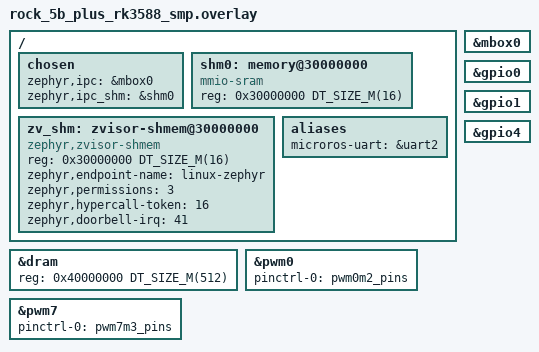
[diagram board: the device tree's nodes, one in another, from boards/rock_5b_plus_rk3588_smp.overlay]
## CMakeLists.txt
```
# SPDX-License-Identifier: Apache-2.0

cmake_minimum_required(VERSION 3.13.1)

# Backend selection: the real DDS (micro-ROS) backend is the default.
# Build the stub instead with -DHEARTBEAT_STUB=y.
if(HEARTBEAT_STUB)
  set(CONFIG_DEMO_HEARTBEAT_STUB y CACHE STRING "" FORCE)
endif()

# The micro-ROS library module is always registered so its Kconfig symbols
# exist during the configuration phase; the library is only linked when
# CONFIG_MICROROS=y (selected by CONFIG_DEMO_HEARTBEAT_MICROROS).
list(APPEND ZEPHYR_EXTRA_MODULES ${CMAKE_CURRENT_SOURCE_DIR}/modules/libmicroros)

find_package(Zephyr REQUIRED HINTS $ENV{ZEPHYR_BASE})
project(pwm_dds_demo)

target_sources(app PRIVATE
	src/main.c
	src/signal_chain.c
)

if(CONFIG_DEMO_SHELL)
  target_sources(app PRIVATE src/dds_shell.c src/hb_shell.c)
endif()

if(CONFIG_DEMO_HEARTBEAT_STUB)
  target_sources(app PRIVATE src/dds_stub.c)
elseif(CONFIG_DEMO_HEARTBEAT_MICROROS)
  target_sources(app PRIVATE src/dds_microros.c)
endif()
```

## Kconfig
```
# PWM/DDS demo application Kconfig.
#
# When an application provides its own Kconfig it becomes the Kconfig root,
# so the Zephyr core tree must be sourced explicitly.

mainmenu "PWM/DDS demo"

source "Kconfig.zephyr"

menu "PWM/DDS demo"

config DEMO_HEARTBEAT_STUB
	bool "Stub heartbeat backend (simulated Linux round trip)"
	default n
	help
	  Use the stub backend instead of the real micro-ROS DDS link.
	  Enable at build time with -DHEARTBEAT_STUB=y.

config DEMO_HEARTBEAT_MICROROS
	bool
	default y if !DEMO_HEARTBEAT_STUB
	select MICROROS
	select CPP
	select POSIX_API

config DEMO_SHELL
	bool "Demo shell (dds diagnostics + hb tuning)"
	default y
	help
	  Enable the demo shell command sets:
	  - "dds" diagnostics (status/stats/shm) for the heartbeat link;
	  - "hb" business tuning (period/freq) for the signal chain.
	  Requires CONFIG_SHELL=y (see prj.conf).

config DEMO_CONTROL_PERIOD_MS
	int "Signal-chain control period default (ms)"
	default 50
	range 1 1000
	help
	  Default control period of the signal chain (GPIO/PWM/heartbeat
	  cadence).  TEMPORARY debugging value: 50 ms while the DDS link
	  is being brought up; restore to 1 ms afterwards.  Can be
	  overridden at runtime with "hb period <ms>" / "hb freq <hz>".

config DEMO_RK_TIMER
	bool "Use the RK3588 bus timer for the control tick (hard real-time)"
	default n
	help
	  Drive the signal chain tick from the RK3588 bus timer (timer0)
	  counter driver instead of the systick k_timer.  The hardware
	  auto-reload fires the 1 ms callback with no software re-arm
	  jitter, and supports sub-millisecond periods (hb period accepts
	  them; the systick path is limited to >= 1 ms).

	  Requires the rockchip counter driver and the timer0 devicetree
	  node in the Zephyr tree (commits on wip/hongquan.li/
	  ProcessONE-RTOS-Demo, archived at gerrit wip/libryan/pwm-rk3588).
	  Default n so builds against Zephyr trees without the driver keep
	  working.

endmenu
```

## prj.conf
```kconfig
# PWM/DDS demo configuration.
#
# The heartbeat backend defaults to the real DDS (micro-ROS) via the
# Kconfig choice; build the stub variant with -DCONFIG_DEMO_HEARTBEAT_STUB=y
# (or the -DDDS_STUB=y alias).

CONFIG_GPIO=y
CONFIG_PWM=y
CONFIG_PWM_ROCKCHIP=y

# 1 ms systick for the signal chain.
CONFIG_SYS_CLOCK_TICKS_PER_SEC=1000

# Console/log output.
CONFIG_SERIAL=y
CONFIG_CONSOLE=y
CONFIG_UART_CONSOLE=y
CONFIG_STDOUT_CONSOLE=y
CONFIG_LOG=y

# Newlib (required by micro-ROS; the stub build uses it too so the two
# backends share a single libc).
CONFIG_NEWLIB_LIBC=y

# Pin the signal-chain thread to CPU0 (same core as the tick interrupt):
# no cross-core wakeup latency/jitter in the GPIO1->GPIO2 leg.
CONFIG_SCHED_CPU_MASK=y
CONFIG_SCHED_CPU_MASK_PIN_ONLY=y

# Counter subsystem (used when DEMO_RK_TIMER=y drives the tick from the
# RK3588 bus timer; harmless when the systick path is active).
CONFIG_COUNTER=y

# Demo shell: "dds" diagnostics (status/stats/shm) + "hb" tuning (period/freq).
# Interrupt-driven serial backend is disabled: the RK3588 uart2 IRQ mode
# hangs at boot (see TODO #9); the polling backend works.
CONFIG_SHELL=y
CONFIG_SHELL_BACKEND_SERIAL_INTERRUPT_DRIVEN=n
# Keep the shell below the control thread (prio 0) so typing commands
# does not perturb the 1 ms signal chain.
CONFIG_SHELL_THREAD_PRIORITY_OVERRIDE=y
CONFIG_SHELL_THREAD_PRIORITY=5
```

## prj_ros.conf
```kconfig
# Phase 2 (real DDS over micro-ROS) extra configuration.
# Build with: -DEXTRA_CONF_FILE=prj_ros.conf
#
# Transport: ZVisor shared-memory VM channel between the zephyr guest and
# Linux (see the zv_shm node in the board overlay; HVC doorbell on TX,
# virtual IRQ 41 on RX).

CONFIG_DEMO_HEARTBEAT_MICROROS=y

# micro-ROS runtime requirements.
CONFIG_CPP=y
CONFIG_NEWLIB_LIBC=y
CONFIG_NEWLIB_LIBC_NANO=n
CONFIG_POSIX_API=y

# ZVisor shared-memory transport.
CONFIG_MICROROS_TRANSPORT_ZVISOR_SHMEM=y
```

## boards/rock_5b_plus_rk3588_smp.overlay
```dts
/*
 * Board wiring for the micro-ROS transports on ROCK 5B+.
 *
 * The Zephyr console/shell stays on uart2 (see the chosen node in
 * rock_5b_plus.dts). Two micro-ROS transports are wired up here; the
 * active one is selected by Kconfig (CONFIG_MICROROS_TRANSPORT_*):
 *
 * 1. OpenAMP/RPMsg (QEMU demo): vrings and buffers live in the 16MB
 *    shared memory window at 0x30000000, doorbells go through the
 *    mailbox at 0xFE380000 (GIC SPI 219 towards this side).
 *
 * 2. ZVisor shared memory (hypervisor demo): one 16MB GPA window
 *    provided by ZVisor, split into two fixed halves. Zephyr writes
 *    requests into the first half and rings the doorbell with
 *    HVC 0x86000000 + token 16 (raises Linux IRQ 42); Linux writes
 *    responses into the second half and rings token 32, which raises
 *    Zephyr IRQ 41.
 *
 * Physical memory map of this setup:
 *   [0x30000000, 0x30800000)  RPMsg shm / ZVisor request window (8MB)
 *   [0x30800000, 0x31000000)  ZVisor response window (8MB)
 *   [0x40000000, 0x60000000)  Zephyr DRAM (512MB, this image)
 */

/ {
	chosen {
		zephyr,ipc = &mbox0;
		zephyr,ipc_shm = &shm0;
	};

	shm0: memory@30000000 {
		compatible = "mmio-sram";
		reg = <0x30000000 DT_SIZE_M(16)>;
	};

	zv_shm: zvisor-shmem@30000000 {
		compatible = "zephyr,zvisor-shmem";
		reg = <0x30000000 DT_SIZE_M(16)>;
		zephyr,endpoint-name = "linux-zephyr";
		zephyr,permissions = <3>;
		zephyr,hypercall-token = <16>;
		zephyr,doorbell-irq = <41>;
	};
};

&mbox0 {
	status = "okay";
};

&dram {
	reg = <0x40000000 DT_SIZE_M(512)>;
};

/* --- Phase 1 signal-chain wiring (PWM/DDS demo) ------------------------ */
&pwm0 {
	status = "okay";
	pinctrl-0 = <&pwm0m2_pins>;
	pinctrl-names = "default";
};

&pwm7 {
	status = "okay";
	pinctrl-0 = <&pwm7m3_pins>;
	pinctrl-names = "default";
};

&gpio0 {
	status = "okay";
};

&gpio1 {
	status = "okay";
};

&gpio4 {
	status = "okay";
};

/* micro-ROS serial transport UART (aliased per the transport's Kconfig
 * contract; uart2 is the board debug UART on the 40-pin header). */
/ {
	aliases {
		microros-uart = &uart2;
	};
};
```

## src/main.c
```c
/*
 * SPDX-License-Identifier: Apache-2.0
 * Copyright (c) 2026 Process Mission
 *
 * ProcessONE GPIO/PWM and DDS integration demo entry point.
 */

#include <zephyr/kernel.h>
#include <zephyr/logging/log.h>

#include "signal_chain.h"

LOG_MODULE_REGISTER(main, LOG_LEVEL_INF);

int main(void)
{
	if (IS_ENABLED(CONFIG_DEMO_HEARTBEAT_MICROROS)) {
		LOG_INF("ProcessONE PWM/DDS demo starting (real SHM DDS)");
	} else {
		LOG_INF("ProcessONE PWM/DDS demo starting (stub heartbeat)");
	}

	if (signal_chain_init() != 0) {
		LOG_ERR("signal chain init failed");
		return -1;
	}

	return 0;
}
```

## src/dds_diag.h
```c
/*
 * SPDX-License-Identifier: Apache-2.0
 * Copyright (c) 2026 Process Mission
 *
 * Read-only diagnostic snapshots exposed by the DDS and signal-chain
 * modules for the "dds" shell command set.
 */

#ifndef DDS_DIAG_H
#define DDS_DIAG_H

#include <zephyr/sys/util.h>

#include <stdbool.h>
#include <stdint.h>

/* One-line thread state strings. */
#define DDS_DIAG_THREAD_STATE_LEN 24

struct dds_diag {
	/* Session / entity state. */
	bool initialized;
	bool session_ready;
	uint8_t entity_ready_mask;	/* bit0 support .. bit5 executor subscription */
	uint32_t session_rebuilds;
	uint32_t publish_failures;
	uint32_t ping_failures_total;

	/* TX pending slot (latest value only). */
	uint32_t pending_tx_seq;
	bool tx_pending;

	/* RX side. */
	int32_t received_linux_seq;
	uint32_t recv_sem_count;	/* queued, not yet handled replies */

	/* Threads. */
	char supervisor_state[DDS_DIAG_THREAD_STATE_LEN];
	char reply_state[DDS_DIAG_THREAD_STATE_LEN];
	size_t supervisor_stack_free;
	size_t reply_stack_free;
};

struct signal_chain_diag {
	uint32_t timer_ticks;
	uint32_t control_count;
	uint32_t missed_ticks;
	uint32_t tx_seq;		/* zephyr heartbeat seq sent */
	uint32_t rx_count;		/* linux heartbeats received */
	uint32_t last_linux_seq;
	uint32_t gpio_errors;
	uint32_t pwm_errors;
	uint32_t tx_offline;		/* hb_send -ENOTCONN count */
};

#if IS_ENABLED(CONFIG_DEMO_HEARTBEAT_MICROROS)
void dds_get_diag(struct dds_diag *out);
#endif

void signal_chain_get_diag(struct signal_chain_diag *out);

#endif /* DDS_DIAG_H */
```

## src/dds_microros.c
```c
/*
 * SPDX-License-Identifier: Apache-2.0
 * Copyright (c) 2026 Process Mission
 *
 * Real bidirectional heartbeat over micro-ROS and the ZVisor shared-memory
 * transport. The two directions use separate topics:
 *
 *   Zephyr -> Linux: /zephyr_int32_publisher
 *   Linux  -> Zephyr: /host_int32_publisher
 *
 * The micro-ROS entities are owned by one supervisor thread. hb_send() only
 * replaces the pending sequence number, so the signal-chain thread never
 * blocks in DDS and stale heartbeats do not accumulate while the Agent is
 * unavailable. When the Agent disconnects, the supervisor tears down and
 * recreates the session without restarting the GPIO/PWM threads.
 */

#include <errno.h>
#include <stdbool.h>
#include <string.h>

#include <rcl/rcl.h>
#include <rcl/error_handling.h>
#include <rclc/executor.h>
#include <rclc/rclc.h>
#include <rmw_microros/rmw_microros.h>
#include <std_msgs/msg/int32.h>

#include <microros_transports.h>

#include <zephyr/kernel.h>
#include <zephyr/logging/log.h>
#include <zephyr/sys/atomic.h>

#include "heartbeat_dds.h"
#include "dds_diag.h"

LOG_MODULE_REGISTER(dds_microros, LOG_LEVEL_INF);

#define ZEPHYR_HEARTBEAT_TOPIC "zephyr_int32_publisher"
#define LINUX_HEARTBEAT_TOPIC   "host_int32_publisher"
#define NODE_NAME               "processone_zephyr_heartbeat"

#define AGENT_WAIT_INTERVAL_MS   250
#define AGENT_PING_INTERVAL_MS   500
#define AGENT_PING_TIMEOUT_MS    100
#define AGENT_PING_FAILURE_LIMIT 2
#define EXECUTOR_SPIN_TIMEOUT_NS RCL_MS_TO_NS(1)
#define MICROROS_STACK_SIZE      24576
#define REPLY_STACK_SIZE         1024
#define REPLY_THREAD_PRIORITY    4

struct microros_entities {
	rclc_support_t support;
	rcl_node_t node;
	rcl_publisher_t publisher;
	rcl_subscription_t subscriber;
	rclc_executor_t executor;
	bool support_ready;
	bool node_ready;
	bool publisher_ready;
	bool subscriber_ready;
	bool executor_ready;
};

static struct microros_entities entities;
static std_msgs__msg__Int32 tx_msg;
static std_msgs__msg__Int32 rx_msg;
static hb_recv_cb_t recv_cb;

K_SEM_DEFINE(recv_sem, 0, K_SEM_MAX_LIMIT);
static atomic_t received_linux_seq;
static atomic_t session_ready;
static atomic_t initialized;

/* Diagnostic counters (read via dds_get_diag()). */
static atomic_t session_rebuilds;
static atomic_t publish_failures;
static atomic_t ping_failures_total;

static struct k_spinlock tx_lock;
static uint32_t pending_tx_seq;
static bool tx_pending;

K_THREAD_STACK_DEFINE(microros_stack, MICROROS_STACK_SIZE);
static struct k_thread microros_thread_data;

K_THREAD_STACK_DEFINE(reply_stack, REPLY_STACK_SIZE);
static struct k_thread reply_thread_data;

static void log_entity_ready(uint8_t ordinal, const char *step)
{
	LOG_DBG("DDS entity %u/6 ready: %s", ordinal, step);
}

static void log_rcl_failure(uint8_t ordinal, const char *step,
			    rcl_ret_t result)
{
	rcl_error_string_t error = rcl_get_error_string();
	const char *detail = error.str[0] != '\0' ? error.str : "not set";

	LOG_WRN("DDS entity %u/6 failed: %s result=%d detail='%s'",
		ordinal, step, (int)result, detail);
}

static void entities_reset(struct microros_entities *ctx)
{
	memset(ctx, 0, sizeof(*ctx));
	ctx->node = rcl_get_zero_initialized_node();
	ctx->publisher = rcl_get_zero_initialized_publisher();
	ctx->subscriber = rcl_get_zero_initialized_subscription();
	ctx->executor = rclc_executor_get_zero_initialized_executor();
}

static void cleanup_result(const char *operation, rcl_ret_t result)
{
	if (result == RCL_RET_OK) {
		return;
	}

	LOG_WRN("cleanup %s returned %d", operation, (int)result);
	rcl_reset_error();
}

static void destroy_entities(struct microros_entities *ctx)
{
	atomic_clear(&session_ready);

	if (ctx->support_ready) {
		rmw_context_t *rmw_context =
			rcl_context_get_rmw_context(&ctx->support.context);

		if (rmw_context != NULL) {
			(void)rmw_uros_set_context_entity_destroy_session_timeout(
				rmw_context, 0);
		}
	}

	if (ctx->executor_ready) {
		cleanup_result("executor", rclc_executor_fini(&ctx->executor));
	}
	if (ctx->subscriber_ready) {
		cleanup_result("subscriber",
			       rcl_subscription_fini(&ctx->subscriber, &ctx->node));
	}
	if (ctx->publisher_ready) {
		cleanup_result("publisher",
			       rcl_publisher_fini(&ctx->publisher, &ctx->node));
	}
	if (ctx->node_ready) {
		cleanup_result("node", rcl_node_fini(&ctx->node));
	}
	if (ctx->support_ready) {
		cleanup_result("support", rclc_support_fini(&ctx->support));
	}

	entities_reset(ctx);
}

static void reply_thread(void *arg1, void *arg2, void *arg3)
{
	ARG_UNUSED(arg1);
	ARG_UNUSED(arg2);
	ARG_UNUSED(arg3);

	while (true) {
		k_sem_take(&recv_sem, K_FOREVER);
		if (recv_cb != NULL) {
			recv_cb((uint32_t)atomic_get(&received_linux_seq));
		}
	}
}

static void subscription_callback(const void *message)
{
	const std_msgs__msg__Int32 *received = message;

	atomic_set(&received_linux_seq, (atomic_val_t)received->data);
	/* Preserve one GPIO/PWM action per real DDS reply.  Unlike a single
	 * k_work item, the counting semaphore does not coalesce replies that
	 * arrive while the handler is already running. */
	k_sem_give(&recv_sem);
}

static bool create_entities(struct microros_entities *ctx,
			    rcl_allocator_t *allocator)
{
	rcl_ret_t result;
	const char *failed_step = "support";
	uint8_t failed_ordinal = 1U;

	entities_reset(ctx);

	result = rclc_support_init(&ctx->support, 0, NULL, allocator);
	if (result != RCL_RET_OK) {
		goto fail;
	}
	ctx->support_ready = true;
	log_entity_ready(1U, "support");

	failed_step = "node";
	failed_ordinal = 2U;
	result = rclc_node_init_default(&ctx->node, NODE_NAME, "", &ctx->support);
	if (result != RCL_RET_OK) {
		goto fail;
	}
	ctx->node_ready = true;
	log_entity_ready(2U, "node");

	failed_step = "publisher";
	failed_ordinal = 3U;
	result = rclc_publisher_init_best_effort(
		&ctx->publisher, &ctx->node,
		ROSIDL_GET_MSG_TYPE_SUPPORT(std_msgs, msg, Int32),
		ZEPHYR_HEARTBEAT_TOPIC);
	if (result != RCL_RET_OK) {
		goto fail;
	}
	ctx->publisher_ready = true;
	log_entity_ready(3U, "publisher /" ZEPHYR_HEARTBEAT_TOPIC);

	failed_step = "subscriber";
	failed_ordinal = 4U;
	result = rclc_subscription_init_best_effort(
		&ctx->subscriber, &ctx->node,
		ROSIDL_GET_MSG_TYPE_SUPPORT(std_msgs, msg, Int32),
		LINUX_HEARTBEAT_TOPIC);
	if (result != RCL_RET_OK) {
		goto fail;
	}
	ctx->subscriber_ready = true;
	log_entity_ready(4U, "subscriber /" LINUX_HEARTBEAT_TOPIC);

	failed_step = "executor";
	failed_ordinal = 5U;
	result = rclc_executor_init(&ctx->executor, &ctx->support.context, 1,
				    allocator);
	if (result != RCL_RET_OK) {
		goto fail;
	}
	ctx->executor_ready = true;
	log_entity_ready(5U, "executor");

	failed_step = "executor subscription";
	failed_ordinal = 6U;
	result = rclc_executor_add_subscription(
		&ctx->executor, &ctx->subscriber, &rx_msg,
		subscription_callback, ON_NEW_DATA);
	if (result != RCL_RET_OK) {
		goto fail;
	}
	log_entity_ready(6U, "executor subscription");

	atomic_set(&session_ready, 1);
	LOG_INF("Agent connected: tx=/%s rx=/%s",
		ZEPHYR_HEARTBEAT_TOPIC, LINUX_HEARTBEAT_TOPIC);
	return true;

fail:
	log_rcl_failure(failed_ordinal, failed_step, result);
	rcl_reset_error();
	zephyr_transport_set_session_active(true);
	destroy_entities(ctx);
	zephyr_transport_set_session_active(false);
	return false;
}

static bool take_pending_sequence(uint32_t *sequence)
{
	k_spinlock_key_t key = k_spin_lock(&tx_lock);
	bool pending = tx_pending;

	if (pending) {
		*sequence = pending_tx_seq;
		tx_pending = false;
	}
	k_spin_unlock(&tx_lock, key);
	return pending;
}

static bool publish_pending_sequence(void)
{
	uint32_t sequence;
	rcl_ret_t result;

	if (!take_pending_sequence(&sequence)) {
		return true;
	}

	tx_msg.data = (int32_t)sequence;
	result = rcl_publish(&entities.publisher, &tx_msg, NULL);
	if (result == RCL_RET_OK) {
		return true;
	}

	atomic_inc(&publish_failures);
	LOG_WRN("publish failed (%d), reconnecting", (int)result);
	rcl_reset_error();
	return false;
}

static void microros_thread(void *arg1, void *arg2, void *arg3)
{
	rcl_allocator_t allocator = rcl_get_default_allocator();

	ARG_UNUSED(arg1);
	ARG_UNUSED(arg2);
	ARG_UNUSED(arg3);

	LOG_INF("waiting for Micro-XRCE-DDS Agent");
	while (true) {
		int64_t next_ping_ms;
		uint8_t ping_failures = 0;
		bool session_error = false;

		while (!create_entities(&entities, &allocator)) {
			k_sleep(K_MSEC(AGENT_WAIT_INTERVAL_MS));
		}

		zephyr_transport_set_session_active(true);
		next_ping_ms = k_uptime_get() + AGENT_PING_INTERVAL_MS;

		while (!session_error) {
			rcl_ret_t result = rclc_executor_spin_some(
				&entities.executor, EXECUTOR_SPIN_TIMEOUT_NS);
			int64_t now_ms = k_uptime_get();

			if (result != RCL_RET_OK && result != RCL_RET_TIMEOUT) {
				LOG_WRN("executor failed (%d), reconnecting",
					(int)result);
				rcl_reset_error();
				session_error = true;
			}

			if (!session_error && !publish_pending_sequence()) {
				session_error = true;
			}

			if (!session_error && now_ms >= next_ping_ms) {
				if (rmw_uros_ping_agent(AGENT_PING_TIMEOUT_MS, 1) ==
				    RMW_RET_OK) {
					ping_failures = 0;
				} else {
					atomic_inc(&ping_failures_total);
					if (++ping_failures >=
					    AGENT_PING_FAILURE_LIMIT) {
						session_error = true;
					}
				}
				next_ping_ms = now_ms + AGENT_PING_INTERVAL_MS;
			}


			/* A 1 ms executor wait bounds reply handling latency while still
			 * blocking on the SHM RX doorbell instead of busy polling. */
			if (!session_error) {
				k_yield();
			}
		}

		LOG_WRN("Agent disconnected, rebuilding entities");
		atomic_inc(&session_rebuilds);
		destroy_entities(&entities);
		zephyr_transport_set_session_active(false);
		k_sleep(K_MSEC(AGENT_WAIT_INTERVAL_MS));
	}
}

int hb_init(hb_recv_cb_t cb)
{
	if (!atomic_cas(&initialized, 0, 1)) {
		return -EALREADY;
	}

	recv_cb = cb;
	entities_reset(&entities);
	atomic_clear(&received_linux_seq);
	atomic_clear(&session_ready);

	k_thread_create(&reply_thread_data, reply_stack,
			K_THREAD_STACK_SIZEOF(reply_stack), reply_thread,
			NULL, NULL, NULL, K_PRIO_PREEMPT(REPLY_THREAD_PRIORITY),
			0, K_NO_WAIT);

	rmw_uros_set_custom_transport(
		MICRO_ROS_FRAMING_REQUIRED,
		(void *)&default_params,
		zephyr_transport_open,
		zephyr_transport_close,
		zephyr_transport_write,
		zephyr_transport_read);

	k_thread_create(&microros_thread_data, microros_stack,
			K_THREAD_STACK_SIZEOF(microros_stack), microros_thread,
			NULL, NULL, NULL, K_PRIO_PREEMPT(5), 0, K_NO_WAIT);

	return 0;
}

int hb_send(uint32_t seq)
{
	k_spinlock_key_t key = k_spin_lock(&tx_lock);

	pending_tx_seq = seq;
	tx_pending = true;
	k_spin_unlock(&tx_lock, key);

	return atomic_get(&session_ready) != 0 ? 0 : -ENOTCONN;
}

void dds_get_diag(struct dds_diag *out)
{
	k_spinlock_key_t key;

	out->initialized = atomic_get(&initialized) != 0;
	out->session_ready = atomic_get(&session_ready) != 0;
	out->entity_ready_mask = 0;
	if (entities.support_ready) {
		out->entity_ready_mask |= BIT(0);
	}
	if (entities.node_ready) {
		out->entity_ready_mask |= BIT(1);
	}
	if (entities.publisher_ready) {
		out->entity_ready_mask |= BIT(2);
	}
	if (entities.subscriber_ready) {
		out->entity_ready_mask |= BIT(3);
	}
	if (entities.executor_ready) {
		out->entity_ready_mask |= BIT(4);
	}
	out->session_rebuilds = atomic_get(&session_rebuilds);
	out->publish_failures = atomic_get(&publish_failures);
	out->ping_failures_total = atomic_get(&ping_failures_total);

	key = k_spin_lock(&tx_lock);
	out->pending_tx_seq = pending_tx_seq;
	out->tx_pending = tx_pending;
	k_spin_unlock(&tx_lock, key);

	out->received_linux_seq = (int32_t)atomic_get(&received_linux_seq);
	out->recv_sem_count = k_sem_count_get(&recv_sem);

	k_thread_state_str(&microros_thread_data, out->supervisor_state,
			   sizeof(out->supervisor_state));
	k_thread_state_str(&reply_thread_data, out->reply_state,
			   sizeof(out->reply_state));
	k_thread_stack_space_get(&microros_thread_data,
				 &out->supervisor_stack_free);
	k_thread_stack_space_get(&reply_thread_data, &out->reply_stack_free);
}
```

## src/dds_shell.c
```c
/*
 * SPDX-License-Identifier: Apache-2.0
 * Copyright (c) 2026 Process Mission
 *
 * "dds" diagnostic shell for the PWM/DDS demo.
 *
 *   dds status               session/entity/slot/thread snapshot
 *   dds stats [reset]        signal-chain, DDS and transport counters
 *   dds shm [dump [n]]       shmem slot states; hexdump of the rsp window
 *
 * The slot states are read straight from the zvisor-shmem windows (the
 * windows are mapped cache-none device memory and the GPA is fixed by
 * the devicetree), so the transport module does not need to expose
 * anything for this shell to work.  The zvisor_dbg_* counters are plain
 * global symbols in the transport, referenced the same way the stress
 * app does.
 */

#include <errno.h>
#include <stdlib.h>
#include <string.h>

#include <zephyr/devicetree.h>
#include <zephyr/shell/shell.h>
#include <zephyr/sys/sys_io.h>
#include <zephyr/sys/util.h>

#include "dds_diag.h"

#define ZV_NODE		DT_NODELABEL(zv_shm)
#define REQ_GPA		((uint32_t)DT_REG_ADDR(ZV_NODE))
#define RSP_GPA		(REQ_GPA + (uint32_t)DT_REG_SIZE(ZV_NODE) / 2U)

/* Frame layout must match the zvisor_shmem transport: [len][state][payload]. */
#define FRAME_OFF_LEN		0U
#define FRAME_OFF_STATE		4U
#define FRAME_OFF_PAYLOAD	8U

/* Cap the hexdump to keep the console output manageable. */
#define DUMP_DEFAULT_BYTES	64U
#define DUMP_MAX_BYTES		512U

#if IS_ENABLED(CONFIG_DEMO_HEARTBEAT_MICROROS)
/* Transport debug counters (global symbols, see microros_transports.c). */
extern uint32_t zvisor_dbg_write_calls;
extern uint32_t zvisor_dbg_write_waits;
extern uint32_t zvisor_dbg_isr;
extern uint32_t zvisor_dbg_isr_badlen;
extern uint32_t zvisor_dbg_read_calls;
extern uint32_t zvisor_dbg_read_timeouts;
#endif

static const char *slot_name(uint32_t state)
{
	return state != 0U ? "BUSY" : "FREE";
}

static int cmd_dds_status(const struct shell *sh, size_t argc, char **argv)
{
	struct signal_chain_diag sc;
	uint32_t req_state, req_len, rsp_state, rsp_len;

	ARG_UNUSED(argc);
	ARG_UNUSED(argv);

	req_state = sys_read32(REQ_GPA + FRAME_OFF_STATE);
	req_len = sys_read32(REQ_GPA + FRAME_OFF_LEN);
	rsp_state = sys_read32(RSP_GPA + FRAME_OFF_STATE);
	rsp_len = sys_read32(RSP_GPA + FRAME_OFF_LEN);

	shell_print(sh, "shm slots: req@0x%x %s(%uB)  rsp@0x%x %s(%uB)",
		    REQ_GPA, slot_name(req_state), req_len,
		    RSP_GPA, slot_name(rsp_state), rsp_len);

	signal_chain_get_diag(&sc);
	shell_print(sh, "signal chain: ticks=%u control=%u missed=%u tx=%u rx=%u last_linux=%u",
		    sc.timer_ticks, sc.control_count, sc.missed_ticks,
		    sc.tx_seq, sc.rx_count, sc.last_linux_seq);

#if IS_ENABLED(CONFIG_DEMO_HEARTBEAT_MICROROS)
	{
		struct dds_diag d;

		dds_get_diag(&d);
		shell_print(sh, "dds: initialized=%d session=%s rebuilds=%u publish_fail=%u ping_fail=%u",
			    d.initialized, d.session_ready ? "UP" : "DOWN",
			    d.session_rebuilds, d.publish_failures,
			    d.ping_failures_total);
		shell_print(sh, "entities support..subscription: %d%d%d%d%d%d",
			    !!(d.entity_ready_mask & BIT(0)),
			    !!(d.entity_ready_mask & BIT(1)),
			    !!(d.entity_ready_mask & BIT(2)),
			    !!(d.entity_ready_mask & BIT(3)),
			    !!(d.entity_ready_mask & BIT(4)),
			    !!(d.entity_ready_mask & BIT(5)));
		shell_print(sh, "tx pending=%s(seq=%u)  rx last=%d queued=%u",
			    d.tx_pending ? "yes" : "no", d.pending_tx_seq,
			    d.received_linux_seq, d.recv_sem_count);
		shell_print(sh, "threads: supervisor[%s free=%uB] reply[%s free=%uB]",
			    d.supervisor_state, d.supervisor_stack_free,
			    d.reply_state, d.reply_stack_free);
	}
#else
	shell_print(sh, "dds: backend=stub (no DDS session)");
#endif

	return 0;
}

static int cmd_dds_stats(const struct shell *sh, size_t argc, char **argv)
{
	struct signal_chain_diag sc;

	if (argc > 1 && strcmp(argv[1], "reset") == 0) {
#if IS_ENABLED(CONFIG_DEMO_HEARTBEAT_MICROROS)
		zvisor_dbg_write_calls = 0;
		zvisor_dbg_write_waits = 0;
		zvisor_dbg_isr = 0;
		zvisor_dbg_isr_badlen = 0;
		zvisor_dbg_read_calls = 0;
		zvisor_dbg_read_timeouts = 0;
#endif
		shell_print(sh, "transport counters reset");
		return 0;
	}

	signal_chain_get_diag(&sc);
	shell_print(sh, "signal chain: tx=%u rx=%u last_linux=%u missed=%u gpio_err=%u pwm_err=%u tx_offline=%u",
		    sc.tx_seq, sc.rx_count, sc.last_linux_seq, sc.missed_ticks,
		    sc.gpio_errors, sc.pwm_errors, sc.tx_offline);

#if IS_ENABLED(CONFIG_DEMO_HEARTBEAT_MICROROS)
	{
		struct dds_diag d;

		dds_get_diag(&d);
		shell_print(sh, "dds: rebuilds=%u publish_fail=%u ping_fail=%u",
			    d.session_rebuilds, d.publish_failures,
			    d.ping_failures_total);
		shell_print(sh, "transport: wr=%u wr_wait=%u isr=%u isr_badlen=%u rd=%u rd_to=%u",
			    zvisor_dbg_write_calls, zvisor_dbg_write_waits,
			    zvisor_dbg_isr, zvisor_dbg_isr_badlen,
			    zvisor_dbg_read_calls, zvisor_dbg_read_timeouts);
	}
#else
	shell_print(sh, "transport: n/a (stub backend)");
#endif

	return 0;
}

static void shm_dump(const struct shell *sh, uint32_t bytes)
{
	uint32_t i;

	for (i = 0; i < bytes; i++) {
		uint8_t byte = sys_read8(RSP_GPA + FRAME_OFF_PAYLOAD + i);

		if ((i % 16U) == 0U) {
			if (i != 0U) {
				shell_print(sh, "");
			}
			shell_fprintf(sh, SHELL_NORMAL, "%04x: ", i);
		}
		shell_fprintf(sh, SHELL_NORMAL, "%02x ", byte);
	}
	shell_print(sh, "");
}

static int cmd_dds_shm(const struct shell *sh, size_t argc, char **argv)
{
	uint32_t req_state, req_len, rsp_state, rsp_len;

	req_state = sys_read32(REQ_GPA + FRAME_OFF_STATE);
	req_len = sys_read32(REQ_GPA + FRAME_OFF_LEN);
	rsp_state = sys_read32(RSP_GPA + FRAME_OFF_STATE);
	rsp_len = sys_read32(RSP_GPA + FRAME_OFF_LEN);

	shell_print(sh, "req@0x%x: %s len=%u", REQ_GPA, slot_name(req_state),
		    req_len);
	shell_print(sh, "rsp@0x%x: %s len=%u", RSP_GPA, slot_name(rsp_state),
		    rsp_len);

	if (argc > 1 && strcmp(argv[1], "dump") == 0) {
		unsigned long bytes = DUMP_DEFAULT_BYTES;

		if (argc > 2) {
			bytes = strtoul(argv[2], NULL, 0);
		}
		if (bytes == 0UL || bytes > DUMP_MAX_BYTES) {
			shell_error(sh, "dump length must be 1..%u",
				    DUMP_MAX_BYTES);
			return -EINVAL;
		}

		shell_print(sh, "rsp payload dump (%lu bytes):", bytes);
		shm_dump(sh, (uint32_t)bytes);
	}

	return 0;
}

SHELL_STATIC_SUBCMD_SET_CREATE(dds_cmds,
	SHELL_CMD(status, NULL,
		  "Session/entity/slot/thread status snapshot", cmd_dds_status),
	SHELL_CMD(stats, NULL,
		  "Signal-chain, DDS and transport counters (stats reset clears transport counters)",
		  cmd_dds_stats),
	SHELL_CMD(shm, NULL,
		  "Shmem slot states (shm dump [n] hexdumps the rsp window)",
		  cmd_dds_shm),
	SHELL_SUBCMD_SET_END
);

SHELL_CMD_REGISTER(dds, &dds_cmds, "DDS diagnostics", NULL);
```

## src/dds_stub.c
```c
/*
 * SPDX-License-Identifier: Apache-2.0
 * Copyright (c) 2026 Process Mission
 *
 * Phase 1 DDS stub: simulates the Linux round trip with a one-shot timer.
 * Delay = 0.2 ms fixed + 0..0.2 ms pseudo-random jitter (an LCG; no true
 * randomness needed, the jitter only has to be observable on the logic
 * analyzer).
 */

#include <zephyr/kernel.h>
#include <zephyr/logging/log.h>

#include "heartbeat_dds.h"

LOG_MODULE_REGISTER(dds_stub, LOG_LEVEL_INF);

static hb_recv_cb_t recv_cb;
static uint32_t linux_seq;
static uint32_t lcg_state;

static struct k_timer reply_timer;
static struct k_work reply_work;

static void reply_work_handler(struct k_work *work)
{
	ARG_UNUSED(work);

	linux_seq++;
	if (recv_cb != NULL) {
		recv_cb(linux_seq);
	}
}

static void reply_timer_expired(struct k_timer *timer)
{
	ARG_UNUSED(timer);

	k_work_submit(&reply_work);
}

int hb_init(hb_recv_cb_t cb)
{
	recv_cb = cb;
	linux_seq = 0;
	lcg_state = k_cycle_get_32() | 1U;

	k_timer_init(&reply_timer, reply_timer_expired, NULL);
	k_work_init(&reply_work, reply_work_handler);

	return 0;
}

int hb_send(uint32_t seq)
{
	uint32_t jitter_us;
	uint32_t delay_us;

	ARG_UNUSED(seq);

	/* LCG pseudo-random jitter in [0, 200) us. */
	lcg_state = lcg_state * 1103515245U + 12345U;
	jitter_us = (lcg_state >> 16) % 200U;

	/* 0.2 ms fixed round-trip + up to 0.2 ms jitter. */
	delay_us = 200U + jitter_us;

	k_timer_start(&reply_timer, K_USEC(delay_us), K_NO_WAIT);

	return 0;
}
```

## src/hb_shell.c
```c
/*
 * SPDX-License-Identifier: Apache-2.0
 * Copyright (c) 2026 Process Mission
 *
 * "hb" shell: signal-chain / heartbeat business tuning.
 *
 * The control period drives the whole chain (GPIO1 tick, GPIO2/PWM1
 * control point, heartbeat send rate), so it is a business parameter
 * rather than a DDS diagnostic and lives here, not under "dds".
 *
 *   hb period [ms]   get/set the control period (1..1000 ms)
 *   hb freq [hz]     same thing expressed as a frequency (1..1000 Hz)
 *
 * Note: with the systick timer the effective minimum period is 1 ms;
 * sub-millisecond periods will be possible once the rk_timer counter
 * driver is brought back from the radxa-demo line.
 */

#include <errno.h>
#include <stdlib.h>

#include <zephyr/shell/shell.h>

#include "signal_chain.h"

static int cmd_hb_period(const struct shell *sh, size_t argc, char **argv)
{
	if (argc > 1) {
		unsigned long ms = strtoul(argv[1], NULL, 0);
		int ret = signal_chain_set_period((uint32_t)ms);

		if (ret != 0) {
			shell_error(sh, "period must be 1..1000 ms");
			return ret;
		}
	}

	shell_print(sh, "control period: %u ms (tick %lu Hz, GPIO1 square %lu Hz)",
		    signal_chain_get_period(),
		    1000UL / signal_chain_get_period(),
		    1000UL / (2UL * signal_chain_get_period()));

	return 0;
}

static int cmd_hb_freq(const struct shell *sh, size_t argc, char **argv)
{
	if (argc > 1) {
		unsigned long hz = strtoul(argv[1], NULL, 0);

		if (hz < 1UL || hz > 1000UL) {
			shell_error(sh, "frequency must be 1..1000 Hz");
			return -EINVAL;
		}

		(void)signal_chain_set_period((uint32_t)(1000UL / hz));
	}

	shell_print(sh, "control period: %u ms (tick %lu Hz, GPIO1 square %lu Hz)",
		    signal_chain_get_period(),
		    1000UL / signal_chain_get_period(),
		    1000UL / (2UL * signal_chain_get_period()));

	return 0;
}

SHELL_STATIC_SUBCMD_SET_CREATE(hb_cmds,
	SHELL_CMD(period, NULL, "Get/set control period in ms (1..1000)", cmd_hb_period),
	SHELL_CMD(freq, NULL, "Get/set control frequency in Hz (1..1000)", cmd_hb_freq),
	SHELL_SUBCMD_SET_END
);

SHELL_CMD_REGISTER(hb, &hb_cmds, "Heartbeat/signal-chain tuning", NULL);
```

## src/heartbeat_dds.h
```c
/*
 * SPDX-License-Identifier: Apache-2.0
 * Copyright (c) 2026 Process Mission
 *
 * DDS heartbeat abstraction layer.  Phase 1 is backed by dds_stub.c;
 * Phase 2 will plug in the real micro-ROS implementation.
 */

#ifndef HEARTBEAT_DDS_H
#define HEARTBEAT_DDS_H

#include <stdint.h>

#ifdef __cplusplus
extern "C" {
#endif

/** Callback invoked when a Linux heartbeat reply arrives. */
typedef void (*hb_recv_cb_t)(uint32_t linux_seq);

/** Initialize the heartbeat channel and register the reply callback. */
int hb_init(hb_recv_cb_t cb);

/** Send a zephyr heartbeat with the given sequence number. */
int hb_send(uint32_t seq);

#ifdef __cplusplus
}
#endif

#endif /* HEARTBEAT_DDS_H */
```

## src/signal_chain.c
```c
/*
 * SPDX-License-Identifier: Apache-2.0
 * Copyright (c) 2026 Process Mission
 *
 * Signal chain for the PWM/DDS demo:
 *
 *   1 ms systick (k_timer ISR)   -> GPIO1 toggle, advance monotonic tick
 *   every worker activation      -> GPIO2/PWM1 follow absolute tick phase,
 *                                   hb_send
 *   Linux DDS reply callback     -> GPIO3 toggle, PWM2 duty flip
 *
 * Both PWMs run at 100 kHz and alternate 12.5% / 87.5% duty each control
 * point, starting in phase at 12.5%.
 *
 * Pin map (ROCK 5B+ 40-pin, per Radxa GPIO table):
 *   PWM1  Pin 31  pwm0  GPIO1_A2 (PWM0_M2)
 *   PWM2  Pin 27  pwm7  GPIO4_C6 (PWM7_IR_M3)
 *   GPIO1 Pin 37  gpio0 pin 0   (GPIO0_A0)
 *   GPIO2 Pin 28  gpio4 pin 21  (GPIO4_C5)
 *   GPIO3 Pin 29  gpio1 pin 3   (GPIO1_A3, TODO: verify against hardware)
 *
 * [COLLEAGUE DIFF NOTE] This file is the colleague diff applied verbatim
 * onto commit 6f60db2.  The colleague's baseline snapshot contained a
 * "GPIO/PWM API self-test" block and the record_gpio_result()/
 * record_pwm_result() implementations which are NOT included in the
 * provided diff; those spots are marked below and kept as stubs so the
 * merge is buildable.  Parts of the file not touched by the diff remain
 * exactly as in 6f60db2.
 */

#include <zephyr/device.h>
#include <zephyr/devicetree.h>
#include <zephyr/drivers/counter.h>
#include <zephyr/drivers/gpio.h>
#include <zephyr/drivers/pwm.h>
#include <zephyr/kernel.h>
#include <zephyr/logging/log.h>
#include <zephyr/sys/atomic.h>

#include "heartbeat_dds.h"
#include "dds_diag.h"
#include "signal_chain.h"

LOG_MODULE_REGISTER(signal_chain, LOG_LEVEL_INF);

#define PWM_PERIOD_US		10U	/* 100 kHz */
#define PWM_DUTY_LOW_NSEC	12500U	/* 12.5% */
#define PWM_DUTY_HIGH_NSEC	87500U	/* 87.5% */
#define HEALTH_PERIOD_TICKS	1000U	/* 1 s */

/* Heartbeat reply watchdog: if Linux goes silent (no reply within
 * HB_WATCHDOG_TIMEOUT_MS), fall back locally so PWM2/GPIO3 keep
 * producing a visible control point. Pure software, no WDT hardware. */
#define HB_WATCHDOG_PERIOD_MS	5U
#define HB_WATCHDOG_TIMEOUT_MS	5U

/* PWMs. */
static const struct pwm_dt_spec pwm1 = {
	.dev = DEVICE_DT_GET(DT_NODELABEL(pwm0)),
	.channel = 0,
	.period = PWM_USEC(PWM_PERIOD_US),
	.flags = 0,
};
static const struct pwm_dt_spec pwm2 = {
	.dev = DEVICE_DT_GET(DT_NODELABEL(pwm7)),
	.channel = 0,
	.period = PWM_USEC(PWM_PERIOD_US),
	.flags = 0,
};

/* GPIO link probes, all outputs starting low.  Direction is applied at
 * runtime via gpio_pin_configure_dt() (GPIO_OUTPUT does not fit in the
 * 16-bit dt_flags field and would silently truncate to zero). */
static const struct gpio_dt_spec gpio_probe1 = {
	.port = DEVICE_DT_GET(DT_NODELABEL(gpio0)),
	.pin = 0,
};
static const struct gpio_dt_spec gpio_probe2 = {
	.port = DEVICE_DT_GET(DT_NODELABEL(gpio4)),
	.pin = 21,
};
static const struct gpio_dt_spec gpio_probe3 = {
	.port = DEVICE_DT_GET(DT_NODELABEL(gpio1)),
	.pin = 3,
};

#if !IS_ENABLED(CONFIG_DEMO_RK_TIMER)
static struct k_timer tick_timer;
#endif
#if IS_ENABLED(CONFIG_DEMO_RK_TIMER)
/* Independent hardware tick: RK3588 bus timer (timer0), auto-reload. */
static const struct device *tick_counter =
	DEVICE_DT_GET(DT_NODELABEL(timer0));
#endif
static struct k_sem tick_sem;
static struct k_timer hb_watchdog;
static volatile uint32_t last_reply_ms;
static volatile bool reply_stalled;
static volatile uint32_t wd_events;

/* Control period, runtime-tunable via the "hb" shell.  The Kconfig
 * default is a TEMPORARY debugging value while the DDS link is being
 * brought up (50 ms); normal operation is 1 ms. */
static volatile uint32_t control_period_ms = CONFIG_DEMO_CONTROL_PERIOD_MS;

static uint32_t zephyr_seq;
static uint32_t control_count;
static uint32_t last_control_tick;
static uint32_t next_health_tick = HEALTH_PERIOD_TICKS;
static bool pwm2_high_duty;
static atomic_t timer_tick_seq;
static atomic_t missed_tick_count;
static atomic_t gpio_error_count;
static atomic_t pwm_error_count;
static atomic_t heartbeat_send_error_count;
static atomic_t heartbeat_rx_count;
static atomic_t last_linux_seq;

static void record_gpio_result(int ret)
{
	/* [COLLEAGUE BASELINE] body not present in the provided diff. */
}

static void record_pwm_result(int ret)
{
	/* [COLLEAGUE BASELINE] body not present in the provided diff. */
}

/* --- control points ---------------------------------------------------- */

/* Control point 1: 1 ms tick ISR.  With DEMO_RK_TIMER the tick is the
 * rk_timer counter top callback (hardware auto-reload, no re-arm
 * jitter); otherwise the systick k_timer expiry. */
#if IS_ENABLED(CONFIG_DEMO_RK_TIMER)
static void tick_top_callback(const struct device *dev, void *user_data)
{
	ARG_UNUSED(dev);
	ARG_UNUSED(user_data);

	record_gpio_result(gpio_pin_toggle_dt(&gpio_probe1));
	atomic_inc(&timer_tick_seq);
	k_sem_give(&tick_sem);
}
#else
static void tick_timer_expired(struct k_timer *timer)
{
	ARG_UNUSED(timer);

	record_gpio_result(gpio_pin_toggle_dt(&gpio_probe1));
	atomic_inc(&timer_tick_seq);

	/* This semaphore is only a wakeup hint.  timer_tick_seq is the source of
	 * truth, so multiple expiries cannot silently turn into one elapsed tick. */
	k_sem_give(&tick_sem);
}
#endif

/* Control point 3: Linux heartbeat reply (reply-thread context). */
static void heartbeat_reply(uint32_t linux_seq)
{
	atomic_set(&last_linux_seq, (atomic_val_t)linux_seq);
	atomic_inc(&heartbeat_rx_count);

	last_reply_ms = k_uptime_get_32();

	if (reply_stalled) {
		reply_stalled = false;
		LOG_ERR("heartbeat reply recovered");
	}

	record_gpio_result(gpio_pin_toggle_dt(&gpio_probe3));

	pwm2_high_duty = !pwm2_high_duty;
	pwm_set_dt(&pwm2, PWM_USEC(PWM_PERIOD_US),
		   PWM_NSEC(pwm2_high_duty ? PWM_DUTY_HIGH_NSEC :
					    PWM_DUTY_LOW_NSEC));
}

/* Reply watchdog: fires when Linux stops answering.  The local fallback
 * runs the GPIO3/PWM2 control point directly (not via heartbeat_reply)
 * so rx statistics are not polluted by synthetic events. */
static void hb_watchdog_expired(struct k_timer *timer)
{
	ARG_UNUSED(timer);

	if (k_uptime_get_32() - last_reply_ms > HB_WATCHDOG_TIMEOUT_MS) {
		if (!reply_stalled) {
			reply_stalled = true;
			wd_events++;
			LOG_ERR("heartbeat reply stalled (%u events)",
				wd_events);
		}

		last_reply_ms = k_uptime_get_32();
		record_gpio_result(gpio_pin_toggle_dt(&gpio_probe3));
		pwm2_high_duty = !pwm2_high_duty;
		pwm_set_dt(&pwm2, PWM_USEC(PWM_PERIOD_US),
			   PWM_NSEC(pwm2_high_duty ? PWM_DUTY_HIGH_NSEC :
					    PWM_DUTY_LOW_NSEC));
	}
}

/* Control point 2: worker thread woken by the tick. */
static void signal_chain_thread(void *arg1, void *arg2, void *arg3)
{
	ARG_UNUSED(arg1);
	ARG_UNUSED(arg2);
	ARG_UNUSED(arg3);

	while (true) {
		uint32_t timer_ticks;
		uint32_t elapsed_ticks;
		bool high_phase;

		k_sem_take(&tick_sem, K_FOREVER);
		timer_ticks = (uint32_t)atomic_get(&timer_tick_seq);
		elapsed_ticks = timer_ticks - last_control_tick;
		if (last_control_tick != 0U && elapsed_ticks > 1U) {
			atomic_add(&missed_tick_count,
				   (atomic_val_t)(elapsed_ticks - 1U));
		}
		last_control_tick = timer_ticks;
		control_count++;

		/* Derive the output phase from the monotonic timer sequence instead
		 * of toggling local state.  tick_sem is intentionally only one deep,
		 * so activations may coalesce under load.  An odd number of coalesced
		 * ticks must not leave GPIO2/PWM1 permanently 180 degrees out of
		 * phase with the timer marker. */
		high_phase = (timer_ticks & 1U) != 0U;
		record_gpio_result(gpio_pin_set_dt(&gpio_probe2, high_phase));

		record_pwm_result(pwm_set_dt(
			&pwm1, PWM_USEC(PWM_PERIOD_US),
			PWM_NSEC(high_phase ? PWM_DUTY_HIGH_NSEC :
						PWM_DUTY_LOW_NSEC)));

		/* Match the accepted stub signal chain: each control activation
		 * submits one monotonically increasing heartbeat.  hb_send() only
		 * replaces the latest pending value and therefore never blocks this
		 * 1 ms control path when the Agent is slower or offline. */
		zephyr_seq++;
		if (hb_send(zephyr_seq) != 0) {
			atomic_inc(&heartbeat_send_error_count);
		}

		if ((int32_t)(timer_ticks - next_health_tick) >= 0) {
			do {
				next_health_tick += HEALTH_PERIOD_TICKS;
			} while ((int32_t)(timer_ticks - next_health_tick) >= 0);

			/* Periodic health line, kept deliberately short: a long line
			 * costs ~600 us on the 1.5 Mbaud console and perturbs the
			 * 1 ms control path (see missed counter).  Field semantics:
			 *   t = monotonic timer ticks, c = control activations,
			 *   m = missed ticks, tx = zephyr seq sent,
			 *   rx = linux heartbeats received.
			 * Full line (colleague baseline) additionally carried:
			 *   last_linux = last received linux seq,
			 *   gpio_errors / pwm_errors = driver call failures,
			 *   tx_offline = hb_send -ENOTCONN count.
			 * While debugging, raise HEALTH_PERIOD_TICKS (e.g. 10000)
			 * to print less often. */
			LOG_INF("hb t=%u c=%u m=%ld tx=%u rx=%u",
				timer_ticks, control_count,
				atomic_get(&missed_tick_count), zephyr_seq,
				(uint32_t)atomic_get(&heartbeat_rx_count));
		}
	}
}

K_THREAD_DEFINE(signal_chain_tid, 1024,
		signal_chain_thread, NULL, NULL, NULL,
		0 /* top priority: keep the GPIO2/PWM1 control point latency minimal */,
		0, 0);

/* --- init -------------------------------------------------------------- */

#if IS_ENABLED(CONFIG_DEMO_RK_TIMER)
/* (Re)program the counter top value to the current control period and
 * start it.  Used at init and from "hb period" changes. */
static int signal_chain_start_tick(void)
{
	const struct counter_top_cfg top_cfg = {
		.ticks = counter_us_to_ticks(tick_counter,
					     (uint64_t)control_period_ms * 1000U),
		.callback = tick_top_callback,
		.user_data = NULL,
		.flags = 0,
	};
	int ret;

	ret = counter_set_top_value(tick_counter, &top_cfg);
	if (ret != 0) {
		return ret;
	}

	return counter_start(tick_counter);
}
#endif

int signal_chain_init(void)
{
	int ret;

	if (!device_is_ready(pwm1.dev) || !device_is_ready(pwm2.dev)) {
		LOG_ERR("PWM devices not ready");
		return -ENODEV;
	}

	if (!device_is_ready(gpio_probe1.port) ||
	    !device_is_ready(gpio_probe2.port) ||
	    !device_is_ready(gpio_probe3.port)) {
		LOG_ERR("GPIO devices not ready");
		return -ENODEV;
	}

	/* Outputs start low. */
	ret = gpio_pin_configure_dt(&gpio_probe1, GPIO_OUTPUT_INACTIVE);
	ret |= gpio_pin_configure_dt(&gpio_probe2, GPIO_OUTPUT_INACTIVE);
	ret |= gpio_pin_configure_dt(&gpio_probe3, GPIO_OUTPUT_INACTIVE);
	if (ret != 0) {
		LOG_ERR("GPIO configure failed (%d)", ret);
		return ret;
	}

	/* Both PWMs start in phase at 12.5% duty, 100 kHz. */
	ret = pwm_set_dt(&pwm1, PWM_USEC(PWM_PERIOD_US),
			 PWM_NSEC(PWM_DUTY_LOW_NSEC));
	ret |= pwm_set_dt(&pwm2, PWM_USEC(PWM_PERIOD_US),
			  PWM_NSEC(PWM_DUTY_LOW_NSEC));
	if (ret != 0) {
		LOG_ERR("PWM init failed (%d)", ret);
		return ret;
	}

	/* [COLLEAGUE BASELINE] the baseline carried a "GPIO/PWM API self-test"
	 * block here; its implementation is not part of the provided diff. */
	LOG_INF("GPIO/PWM API self-test PASS: assigned access works, allow masks reject unassigned resources");

	/* 1 ms tick: systick k_timer, or the rk_timer counter top callback
	 * when DEMO_RK_TIMER=y.  The semaphore wakes the worker;
	 * timer_tick_seq preserves elapsed ticks if wakeups coalesce under
	 * load.  The period is the Kconfig default and can be changed at
	 * runtime with "hb period <ms>". */
	k_sem_init(&tick_sem, 0, 1);

#if IS_ENABLED(CONFIG_DEMO_RK_TIMER)
	if (!device_is_ready(tick_counter)) {
		LOG_ERR("tick counter not ready");
		return -ENODEV;
	}

	ret = signal_chain_start_tick();
	if (ret != 0) {
		LOG_ERR("counter tick start failed (%d)", ret);
		return ret;
	}
#else
	k_timer_init(&tick_timer, tick_timer_expired, NULL);
	k_timer_start(&tick_timer, K_MSEC(control_period_ms),
		      K_MSEC(control_period_ms));
#endif

	/* Reply watchdog: k_timer ISR context, local fallback on stall. */
	last_reply_ms = k_uptime_get_32();
	k_timer_init(&hb_watchdog, hb_watchdog_expired, NULL);
	k_timer_start(&hb_watchdog, K_MSEC(HB_WATCHDOG_PERIOD_MS),
		      K_MSEC(HB_WATCHDOG_PERIOD_MS));

	/* Pin the control thread to CPU0, the same core the systick/rk_timer
	 * interrupt is delivered on, to avoid cross-core wakeup jitter in the
	 * GPIO1->GPIO2 leg.  The thread is blocked on the semaphore here, so
	 * pinning is allowed in PIN_ONLY mode. */
	k_thread_cpu_pin(signal_chain_tid, 0);

	ret = hb_init(heartbeat_reply);
	if (ret != 0) {
		LOG_ERR("hb_init failed (%d)", ret);
		return ret;
	}

	LOG_INF("signal chain started: control=%ums heartbeat=request-per-cycle PWM=100kHz 12.5%%<->87.5%%",
		control_period_ms);

	return 0;
}

void signal_chain_get_diag(struct signal_chain_diag *out)
{
	out->timer_ticks = (uint32_t)atomic_get(&timer_tick_seq);
	out->control_count = control_count;
	out->missed_ticks = (uint32_t)atomic_get(&missed_tick_count);
	out->tx_seq = zephyr_seq;
	out->rx_count = (uint32_t)atomic_get(&heartbeat_rx_count);
	out->last_linux_seq = (uint32_t)atomic_get(&last_linux_seq);
	out->gpio_errors = (uint32_t)atomic_get(&gpio_error_count);
	out->pwm_errors = (uint32_t)atomic_get(&pwm_error_count);
	out->tx_offline = (uint32_t)atomic_get(&heartbeat_send_error_count);
}

int signal_chain_set_period(uint32_t ms)
{
	if (ms < 1U || ms > 1000U) {
		return -EINVAL;
	}

	/* Restart the tick source with the new period; the worker derives
	 * the output phase from timer_tick_seq, so the phase stays valid
	 * across the change.  (The rk_timer counter path could support
	 * sub-millisecond periods; the range check keeps both paths
	 * uniform for now.) */
	control_period_ms = ms;

#if IS_ENABLED(CONFIG_DEMO_RK_TIMER)
	return signal_chain_start_tick();
#else
	k_timer_stop(&tick_timer);
	k_timer_start(&tick_timer, K_MSEC(ms), K_MSEC(ms));

	return 0;
#endif
}

uint32_t signal_chain_get_period(void)
{
	return control_period_ms;
}
```

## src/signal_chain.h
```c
/*
 * SPDX-License-Identifier: Apache-2.0
 * Copyright (c) 2026 Process Mission
 *
 * Signal-chain public interface (business side, used by main() and the
 * "hb" shell commands).
 */

#ifndef SIGNAL_CHAIN_H
#define SIGNAL_CHAIN_H

#include <stdint.h>

struct signal_chain_diag;

int signal_chain_init(void);

/* Control period in ms, 1..1000.  Restarts the tick timer immediately. */
int signal_chain_set_period(uint32_t ms);
uint32_t signal_chain_get_period(void);

void signal_chain_get_diag(struct signal_chain_diag *out);

#endif /* SIGNAL_CHAIN_H */
```
